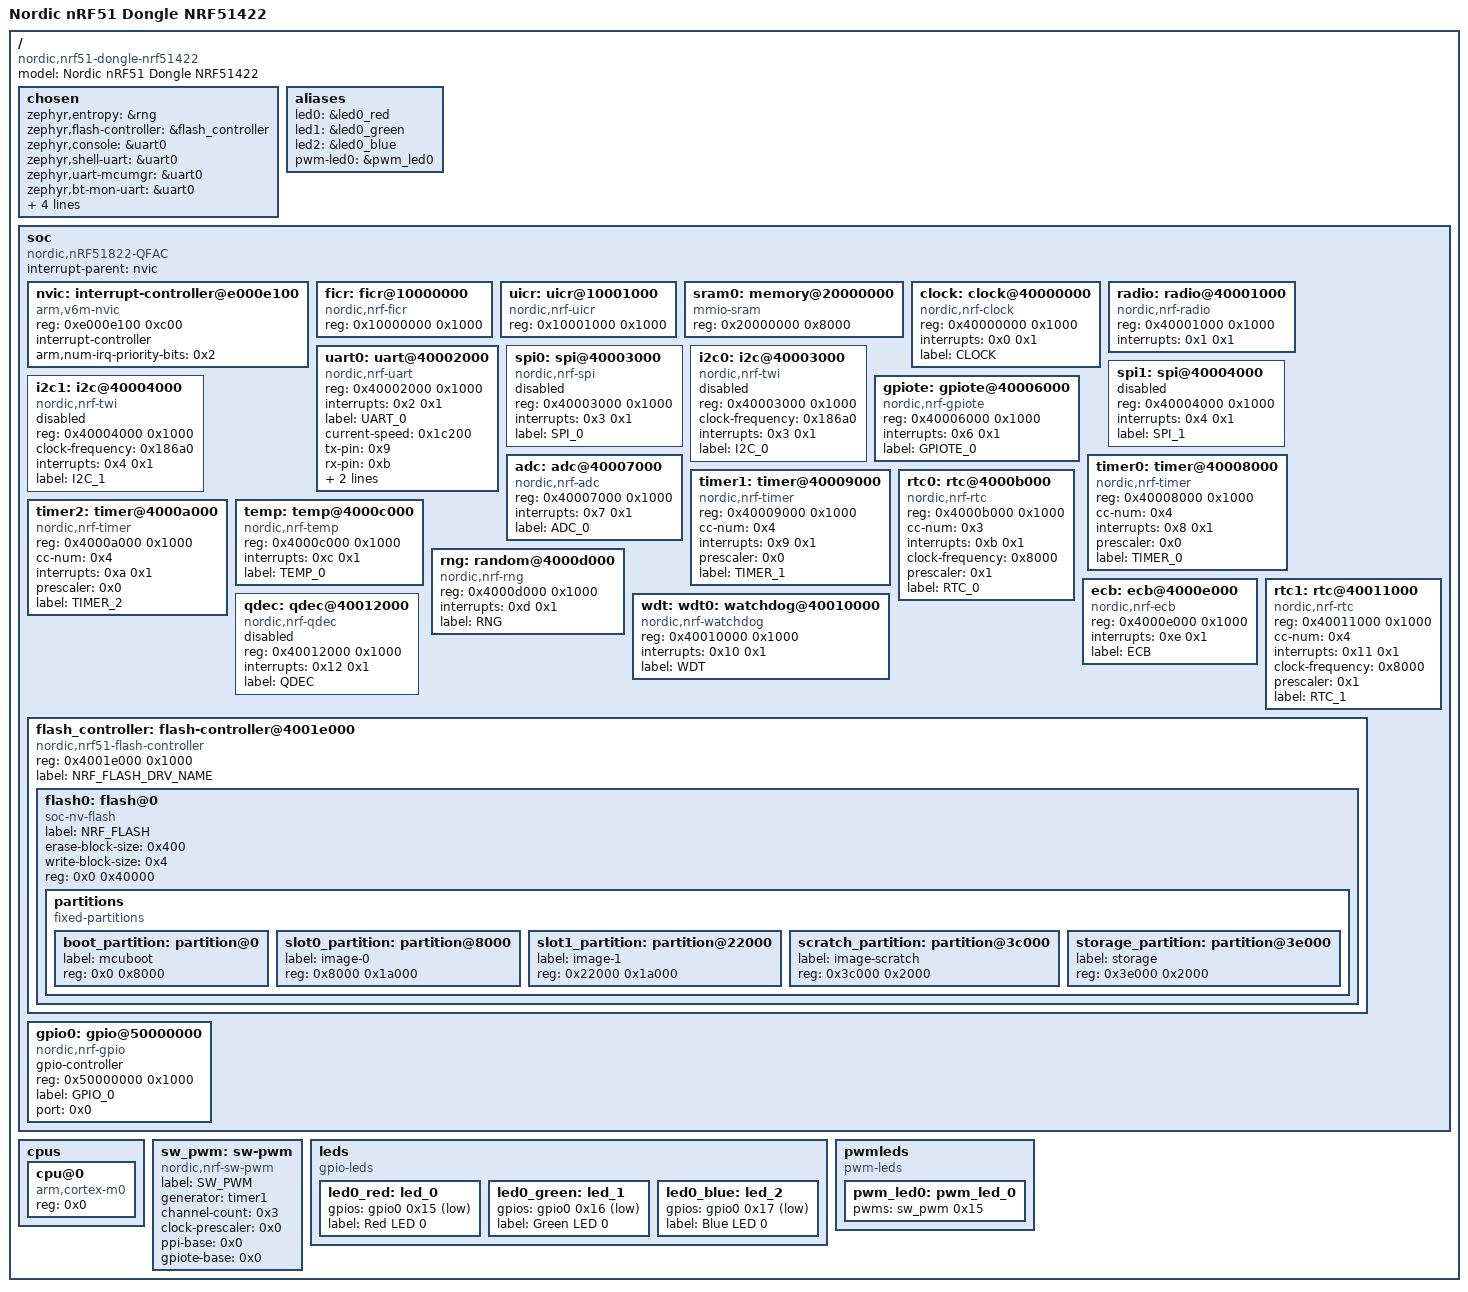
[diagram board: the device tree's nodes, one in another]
/dts-v1/;

/ {
	#address-cells = < 0x1 >;
	#size-cells = < 0x1 >;
	model = "Nordic nRF51 Dongle NRF51422";
	compatible = "nordic,nrf51-dongle-nrf51422";
	chosen {
		zephyr,entropy = &rng;
		zephyr,flash-controller = &flash_controller;
		zephyr,console = &uart0;
		zephyr,shell-uart = &uart0;
		zephyr,uart-mcumgr = &uart0;
		zephyr,bt-mon-uart = &uart0;
		zephyr,bt-c2h-uart = &uart0;
		zephyr,sram = &sram0;
		zephyr,flash = &flash0;
		zephyr,code-partition = &slot0_partition;
	};
	aliases {
		led0 = &led0_red;
		led1 = &led0_green;
		led2 = &led0_blue;
		pwm-led0 = &pwm_led0;
	};
	soc {
		#address-cells = < 0x1 >;
		#size-cells = < 0x1 >;
		compatible = "nordic,nRF51822-QFAC", "nordic,nRF51822", "nordic,nRF51", "simple-bus";
		interrupt-parent = < &nvic >;
		ranges;
		nvic: interrupt-controller@e000e100 {
			#address-cells = < 0x1 >;
			compatible = "arm,v6m-nvic";
			reg = < 0xe000e100 0xc00 >;
			interrupt-controller;
			#interrupt-cells = < 0x2 >;
			arm,num-irq-priority-bits = < 0x2 >;
			phandle = < 0x1 >;
		};
		ficr: ficr@10000000 {
			compatible = "nordic,nrf-ficr";
			reg = < 0x10000000 0x1000 >;
			status = "okay";
		};
		uicr: uicr@10001000 {
			compatible = "nordic,nrf-uicr";
			reg = < 0x10001000 0x1000 >;
			status = "okay";
		};
		sram0: memory@20000000 {
			compatible = "mmio-sram";
			reg = < 0x20000000 0x8000 >;
		};
		clock: clock@40000000 {
			compatible = "nordic,nrf-clock";
			reg = < 0x40000000 0x1000 >;
			interrupts = < 0x0 0x1 >;
			status = "okay";
			label = "CLOCK";
		};
		radio: radio@40001000 {
			compatible = "nordic,nrf-radio";
			reg = < 0x40001000 0x1000 >;
			interrupts = < 0x1 0x1 >;
			status = "okay";
		};
		uart0: uart@40002000 {
			compatible = "nordic,nrf-uart";
			reg = < 0x40002000 0x1000 >;
			interrupts = < 0x2 0x1 >;
			status = "okay";
			label = "UART_0";
			current-speed = < 0x1c200 >;
			tx-pin = < 0x9 >;
			rx-pin = < 0xb >;
			rts-pin = < 0x8 >;
			cts-pin = < 0xa >;
		};
		spi0: spi@40003000 {
			compatible = "nordic,nrf-spi";
			#address-cells = < 0x1 >;
			#size-cells = < 0x0 >;
			reg = < 0x40003000 0x1000 >;
			interrupts = < 0x3 0x1 >;
			status = "disabled";
			label = "SPI_0";
		};
		i2c0: i2c@40003000 {
			compatible = "nordic,nrf-twi";
			#address-cells = < 0x1 >;
			#size-cells = < 0x0 >;
			reg = < 0x40003000 0x1000 >;
			clock-frequency = < 0x186a0 >;
			interrupts = < 0x3 0x1 >;
			status = "disabled";
			label = "I2C_0";
		};
		spi1: spi@40004000 {
			#address-cells = < 0x1 >;
			#size-cells = < 0x0 >;
			reg = < 0x40004000 0x1000 >;
			interrupts = < 0x4 0x1 >;
			status = "disabled";
			label = "SPI_1";
		};
		i2c1: i2c@40004000 {
			compatible = "nordic,nrf-twi";
			#address-cells = < 0x1 >;
			#size-cells = < 0x0 >;
			reg = < 0x40004000 0x1000 >;
			clock-frequency = < 0x186a0 >;
			interrupts = < 0x4 0x1 >;
			status = "disabled";
			label = "I2C_1";
		};
		gpiote: gpiote@40006000 {
			compatible = "nordic,nrf-gpiote";
			reg = < 0x40006000 0x1000 >;
			interrupts = < 0x6 0x1 >;
			status = "okay";
			label = "GPIOTE_0";
		};
		adc: adc@40007000 {
			compatible = "nordic,nrf-adc";
			reg = < 0x40007000 0x1000 >;
			interrupts = < 0x7 0x1 >;
			status = "okay";
			label = "ADC_0";
			#io-channel-cells = < 0x1 >;
		};
		timer0: timer@40008000 {
			compatible = "nordic,nrf-timer";
			status = "okay";
			reg = < 0x40008000 0x1000 >;
			cc-num = < 0x4 >;
			interrupts = < 0x8 0x1 >;
			prescaler = < 0x0 >;
			label = "TIMER_0";
		};
		timer1: timer@40009000 {
			compatible = "nordic,nrf-timer";
			status = "okay";
			reg = < 0x40009000 0x1000 >;
			cc-num = < 0x4 >;
			interrupts = < 0x9 0x1 >;
			prescaler = < 0x0 >;
			label = "TIMER_1";
			phandle = < 0x2 >;
		};
		timer2: timer@4000a000 {
			compatible = "nordic,nrf-timer";
			status = "okay";
			reg = < 0x4000a000 0x1000 >;
			cc-num = < 0x4 >;
			interrupts = < 0xa 0x1 >;
			prescaler = < 0x0 >;
			label = "TIMER_2";
		};
		rtc0: rtc@4000b000 {
			compatible = "nordic,nrf-rtc";
			reg = < 0x4000b000 0x1000 >;
			cc-num = < 0x3 >;
			interrupts = < 0xb 0x1 >;
			status = "okay";
			clock-frequency = < 0x8000 >;
			prescaler = < 0x1 >;
			label = "RTC_0";
		};
		temp: temp@4000c000 {
			compatible = "nordic,nrf-temp";
			reg = < 0x4000c000 0x1000 >;
			interrupts = < 0xc 0x1 >;
			status = "okay";
			label = "TEMP_0";
		};
		rng: random@4000d000 {
			compatible = "nordic,nrf-rng";
			reg = < 0x4000d000 0x1000 >;
			interrupts = < 0xd 0x1 >;
			status = "okay";
			label = "RNG";
		};
		ecb: ecb@4000e000 {
			compatible = "nordic,nrf-ecb";
			reg = < 0x4000e000 0x1000 >;
			interrupts = < 0xe 0x1 >;
			status = "okay";
			label = "ECB";
		};
		wdt: wdt0: watchdog@40010000 {
			compatible = "nordic,nrf-watchdog";
			reg = < 0x40010000 0x1000 >;
			interrupts = < 0x10 0x1 >;
			status = "okay";
			label = "WDT";
		};
		rtc1: rtc@40011000 {
			compatible = "nordic,nrf-rtc";
			reg = < 0x40011000 0x1000 >;
			cc-num = < 0x4 >;
			interrupts = < 0x11 0x1 >;
			status = "okay";
			clock-frequency = < 0x8000 >;
			prescaler = < 0x1 >;
			label = "RTC_1";
		};
		qdec: qdec@40012000 {
			compatible = "nordic,nrf-qdec";
			reg = < 0x40012000 0x1000 >;
			interrupts = < 0x12 0x1 >;
			status = "disabled";
			label = "QDEC";
		};
		flash_controller: flash-controller@4001e000 {
			compatible = "nordic,nrf51-flash-controller";
			reg = < 0x4001e000 0x1000 >;
			#address-cells = < 0x1 >;
			#size-cells = < 0x1 >;
			label = "NRF_FLASH_DRV_NAME";
			flash0: flash@0 {
				compatible = "soc-nv-flash";
				label = "NRF_FLASH";
				erase-block-size = < 0x400 >;
				write-block-size = < 0x4 >;
				reg = < 0x0 0x40000 >;
				partitions {
					compatible = "fixed-partitions";
					#address-cells = < 0x1 >;
					#size-cells = < 0x1 >;
					boot_partition: partition@0 {
						label = "mcuboot";
						reg = < 0x0 0x8000 >;
					};
					slot0_partition: partition@8000 {
						label = "image-0";
						reg = < 0x8000 0x1a000 >;
					};
					slot1_partition: partition@22000 {
						label = "image-1";
						reg = < 0x22000 0x1a000 >;
					};
					scratch_partition: partition@3c000 {
						label = "image-scratch";
						reg = < 0x3c000 0x2000 >;
					};
					storage_partition: partition@3e000 {
						label = "storage";
						reg = < 0x3e000 0x2000 >;
					};
				};
			};
		};
		gpio0: gpio@50000000 {
			compatible = "nordic,nrf-gpio";
			gpio-controller;
			reg = < 0x50000000 0x1000 >;
			#gpio-cells = < 0x2 >;
			label = "GPIO_0";
			status = "okay";
			port = < 0x0 >;
			phandle = < 0x3 >;
		};
	};
	cpus {
		#address-cells = < 0x1 >;
		#size-cells = < 0x0 >;
		cpu@0 {
			device_type = "cpu";
			compatible = "arm,cortex-m0";
			reg = < 0x0 >;
		};
	};
	sw_pwm: sw-pwm {
		compatible = "nordic,nrf-sw-pwm";
		status = "okay";
		label = "SW_PWM";
		generator = < &timer1 >;
		channel-count = < 0x3 >;
		clock-prescaler = < 0x0 >;
		ppi-base = < 0x0 >;
		gpiote-base = < 0x0 >;
		#pwm-cells = < 0x1 >;
		phandle = < 0x4 >;
	};
	leds {
		compatible = "gpio-leds";
		led0_red: led_0 {
			gpios = < &gpio0 0x15 0x1 >;
			label = "Red LED 0";
		};
		led0_green: led_1 {
			gpios = < &gpio0 0x16 0x1 >;
			label = "Green LED 0";
		};
		led0_blue: led_2 {
			gpios = < &gpio0 0x17 0x1 >;
			label = "Blue LED 0";
		};
	};
	pwmleds {
		compatible = "pwm-leds";
		pwm_led0: pwm_led_0 {
			pwms = < &sw_pwm 0x15 >;
		};
	};
};
